# BAT32G133B register map
Vendor: CMS; Series: BAT32G133B; File version: 1.2
CPU: CM0+ r0p1, little endian, no MPU, no FPU, VTOR, 2 interrupt priority bits
Registers are 8-bit, read-write, reset 0x0 unless marked. A register's access mark holds for its fields unless they carry their own. Offsets are from the block's base; [hi:lo] are bit positions; {n}, {i} and the like mark numbered series; 'fields as' and 'values as' point back to an identical list.

## SCI1 — Serial Communication Interface 1 with UART, SPI and simplified I2C supported
Base 0x40041540
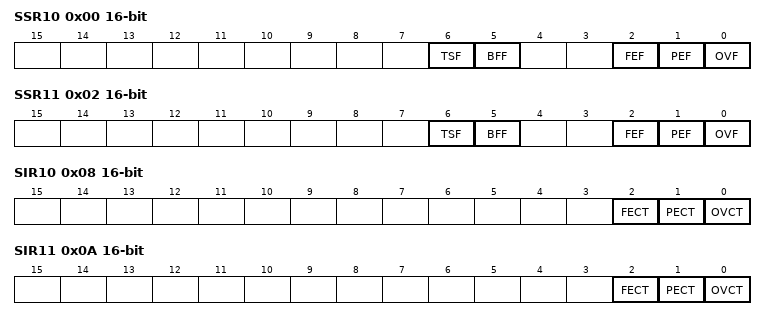
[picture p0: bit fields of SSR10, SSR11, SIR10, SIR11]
0x00 SSR10 16-bit ro — Serial status register mn
  [6] TSF — Communication status indication flag of channel n
  [5] BFF — Buffer register status indication flag of channel n
  [2] FEF — Framing error detection flag of channel n
  [1] PEF — Parity error detection flag of channel n
  [0] OVF — Overrun error detection flag of channel n
0x02 SSR11 16-bit ro — Serial status register mn
  fields as SSR10
0x08 SIR10 16-bit — Serial flag clear trigger register mn
  [2] FECT — Clear trigger of framing error flag of channel n
  [1] PECT — Clear trigger of parity error flag of channel n
  [0] OVCT — Clear trigger of overrun error flag of channel n
0x0A SIR11 16-bit — Serial flag clear trigger register mn
  fields as SIR10
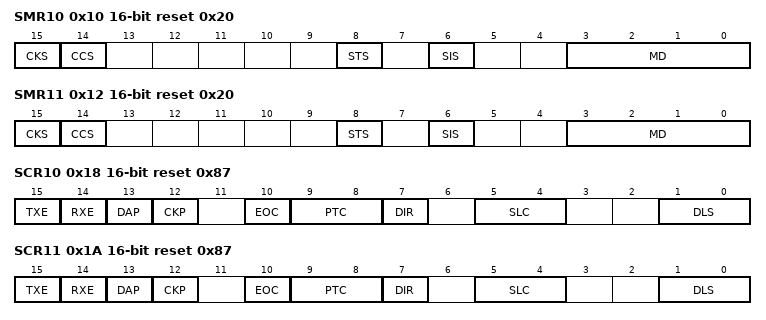
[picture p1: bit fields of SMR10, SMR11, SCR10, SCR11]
0x10 SMR10 16-bit reset 0x20 (reset mask 0xC147) — Serial mode register mn
  [15] CKS — Selection of operation clock (fMCK) of channel n
  [14] CCS — Selection of transfer clock (fTCLK) of channel n
  [8] STS — Selection of start trigger source
  [6] SIS — Controls inversion of level of receive data of channel n in UART mode
  [3:0] MD — Setting of operation mode of channel n
0x12 SMR11 16-bit reset 0x20 (reset mask 0xC147) — Serial mode register mn
  fields as SMR10
0x18 SCR10 16-bit reset 0x87 — Serial communication operation setting register mn
  [15] TXE — Transmission enable
  [14] RXE — Reception enable
  [13] DAP — Selection of data phase in SPI mode
  [12] CKP — Selection of clock phase in SPI mode
  [10] EOC — Mask control of error interrupt signal (INTSREx (x = 0 to 2))
  [9:8] PTC — Setting of parity bit in UART mode
  [7] DIR — Selection of data transfer sequence in SPI and UART modes
  [5:4] SLC — Setting of stop bit in UART mode
  [1:0] DLS — Setting of data length in SPI and UART modes
0x1A SCR11 16-bit reset 0x87 — Serial communication operation setting register mn
  fields as SCR10
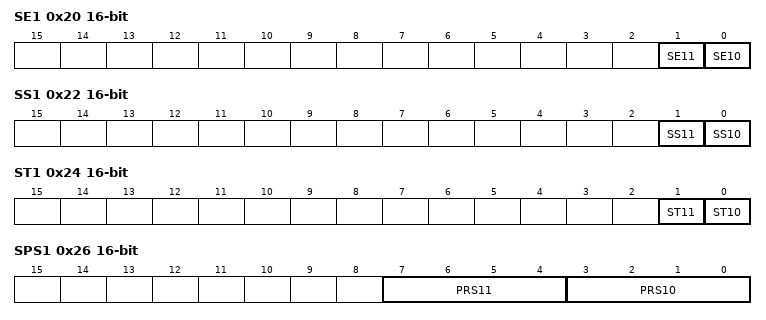
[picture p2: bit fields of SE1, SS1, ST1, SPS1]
0x20 SE1 16-bit ro — Serial channel enable status register 1
  [1] SE11 — Indication of operation enable/stop status of channel 1
  [0] SE10 — Indication of operation enable/stop status of channel 0
0x22 SS1 16-bit — Serial channel start register 1
  [1] SS11 — Operation start trigger of channel 1
  [0] SS10 — Operation start trigger of channel 0
0x24 ST1 16-bit — Serial channel stop register 1
  [1] ST11 — Operation stop trigger of channel 1
  [0] ST10 — Operation stop trigger of channel 0
0x26 SPS1 16-bit — Serial clock select register 1
  [7:4] PRS11 — Prescaler 1
  [3:0] PRS10 — Prescaler 0
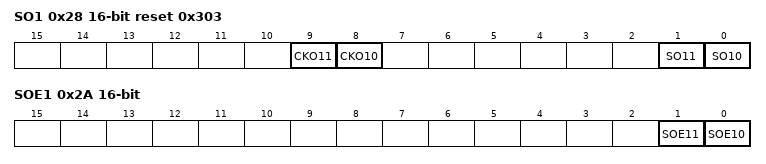
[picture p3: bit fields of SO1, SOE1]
0x28 SO1 16-bit reset 0x303 — Serial output register 1
  [9] CKO11 — Serial clock output of channel 1
  [8] CKO10 — Serial clock output of channel 0
  [1] SO11 — Serial data output of channel 1
  [0] SO10 — Serial data output of channel 0
0x2A SOE1 16-bit — Serial output enable register 1
  [1] SOE11 — Serial output enable of channel 1
  [0] SOE10 — Serial output enable of channel 0
0x34 SOL1 16-bit — Serial output level register 1
  [0] SOL10 — Selects inversion of the level of the transmit data of channel n in UART mode
{0x208+2i} SDR1{i} (i=0..1) 16-bit — Serial data register 1{i}
0x208 SIO20 (alternate view of SDR10) — SPI data register
0x208 TXD2 16-bit (alternate view of SDR10) — UART transmit data register
0x20A SIO21 (alternate view of SDR11) — SPI data register
0x20A RXD2 16-bit (alternate view of SDR11) — UART receive data register

## IICA — Serial Interface I2C with multimaster and wakeup supported
Base 0x40041A30
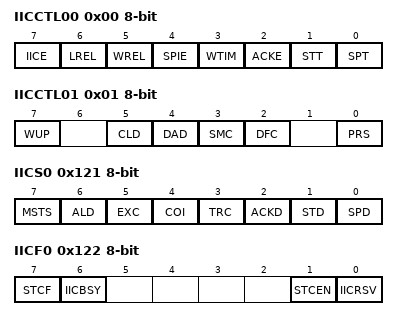
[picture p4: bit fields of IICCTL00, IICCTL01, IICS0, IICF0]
0x00 IICCTL00 — IICA control register 0
  [7] IICE — I2C operation enable
  [6] LREL — Exit from communications
  [5] WREL — Wait cancellation
  [4] SPIE — Enable generation of interrupt request when stop condition is detected
  [3] WTIM — Control of wait and interrupt request generation
  [2] ACKE — Acknowledgment control
  [1] STT — Start condition trigger
  [0] SPT — Stop condition trigger
0x01 IICCTL01 — IICA control register 0
  [7] WUP — Control of address match wakeup
  [5] CLD ro — Detection of SCLAn pin level (valid only when IICEn = 1)
  [4] DAD ro — Detection of SDAAn pin level (valid only when IICEn = 1)
  [3] SMC — Operation mode switching
  [2] DFC — Digital filter operation control
  [0] PRS — Operation clock (fMCK) contro
0x02 IICWL0 reset 0xFF — IICA low-level width setting register 0
0x03 IICWH0 reset 0xFF — IICA high-level width setting register 0
0x04 SVA0 (reset mask 0xFE) — Slave address register 0
0x120 IICA0 — IICA shift register 0
0x121 IICS0 ro — IICA status register 0
  [7] MSTS — Master status check flag
  [6] ALD — Detection of arbitration loss
  [5] EXC — Detection of extension code reception
  [4] COI — Detection of matching addresses
  [3] TRC — Detection of transmit/receive status
  [2] ACKD — Detection of acknowledge (ACK)
  [1] STD — Detection of start condition
  [0] SPD — Detection of stop condition
0x122 IICF0 — IICA flag register 0
  [7] STCF ro — STT clear flag
  [6] IICBSY ro — I2C bus status flag
  [1] STCEN — Initial start enable trigger
  [0] IICRSV — Communication reservation function disable bit
